# NUC122_v1 register map
File version: 1.0
NUC122_v1 SVD file
Registers are 32-bit, read-write, reset 0x0 unless marked. A register's access mark holds for its fields unless they carry their own. Offsets are from the block's base; lines under a group give offsets from that group; [hi:lo] are bit positions; {n}, {i} and the like mark numbered series; 'fields as' and 'values as' point back to an identical list; <NAME> marks a mode.

## Memory map
0x40004000 WDT size 0x4 — WDT Register Map
0x40008000 RTC size 0x34 — RTC Register Map
0x40010000 TMR01 blocks up to offset 0x30 — TMR Register Map
0x40030000 SPI0 blocks up to offset 0x38 — SPI Register Map
0x40034000 SPI1 blocks up to offset 0x38 — SPI Register Map
0x40040000 PWMA blocks up to offset 0x80 — PWM Register Map
0x40050000 UART0 size 0x34 — UART Register Map
0x40060000 USB blocks up to offset 0x94 — USB Register Map
0x40100000 PS2 size 0x20 — PS2 Register Map
0x40110000 TMR23 blocks up to offset 0x30 — TMR Register Map
0x40120000 I2C size 0x34 — I2C Register Map
0x40150000 UART1 size 0x34 — UART Register Map
0x50000000 GCR blocks up to offset 0x104 — GCR Register Map
0x50000200 CLK blocks up to offset 0x24 — CLK Register Map
0x50000300 INT size 0x88 — INT Register Map
0x50004000 GP blocks up to offset 0x300 — GPIO Register Map
0x5000C000 FMC blocks up to offset 0x1C — FMC Register Map
0xE000E000 SCS blocks up to offset 0xD24 — SCS Register Map

## INT — INT Register Map
Base 0x50000300
{0x0+4i} IRQ{i}_SRC ro reset not defined (i=0..3) — IRQ{i} (BOD) Interrupt Source Identity
  [3:0] INT_SRC — Interrupt Source. Define the interrupt sources for interrupt event.
0x10 IRQ4_SRC ro reset not defined — IRQ4(BOD) Interrupt Source Identity
  fields as IRQ0_SRC
{0x0+4i} IRQ{i}_SRC ro reset not defined (i=5..31) — IRQ{i} (BOD) Interrupt Source Identity
  fields as IRQ0_SRC
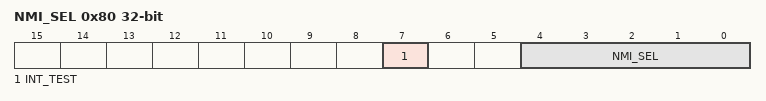
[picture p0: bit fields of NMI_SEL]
0x80 NMI_SEL — NMI Interrupt Source Selection Control Register
  [7] INT_TEST — Interrupt Test Mode (write-protection bit)
  [4:0] NMI_SEL — NMI Interrupt Source Selection. The NMI interrupt to Cortex-M0 can be selected from one of the peripheral interrupts by setting NMI_SEL.
0x84 MCU_IRQ — MCU IRQ Number Identity Register
  [31:0] MCU_IRQ — MCU IRQ Source Register. The MCU_IRQ collects all the interrupts from the peripherals and generates the synchronous interrupt to Cortex-M0. There are two modes to generate interrupt to Cortex-M0, the normal mode and test mode. The MCU_IRQ collects all interrupts from each peripheral and synchronizes them then interrupts the Cortex-M0. When the MCU_IRQ[n] is 0: Set MCU_IRQ[n] 1 will generate an interrupt to Cortex_M0 NVIC[n]. When the MCU_IRQ[n] is 1 (mean an interrupt is assert), set 1 to the MCU_IRQ[n] will clear the interrupt and set MCU_IRQ[n] 0 : no any effect.

## I2C — I2C Register Map
Base 0x40120000
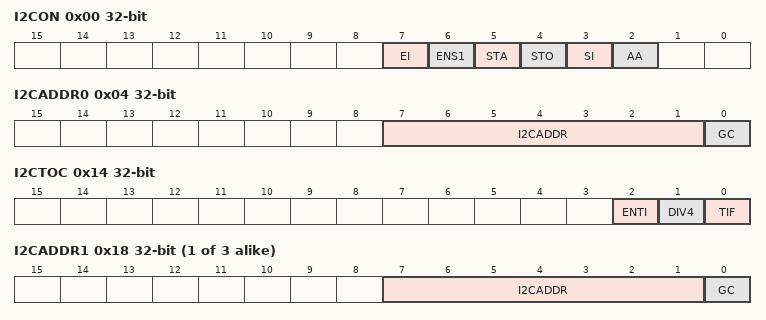
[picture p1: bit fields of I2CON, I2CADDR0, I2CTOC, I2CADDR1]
0x00 I2CON — I2C Control Register
  [7] EI — Enable Interrupt
    0=Disable I2C interrupt; 1=Enable I2C interrupt
  [6] ENS1 — I2C Controller Enable Bit
    0=Disable; 1=Enable
  [5] STA — I2C START Control Bit. Set STA to logic 1 to enter master mode, the I2C hardware sends a START or repeat START condition to bus when the bus is free.
  [4] STO — I2C STOP Control Bit. In master mode, set STO to transmit a STOP condition to bus then I2C hardware will check the bus condition if a STOP condition is detected this bit will be cleared by hardware automatically. In a slave mode, set STO resets I2C hardware to the defined "not addressed" slave mode. This means it is NO LONGER in the slave receiver mode to receive data from the master transmit device.
  [3] SI — I2C Interrupt Flag. When a new I2C state is present in the I2CSTATUS register, the SI flag is set by hardware, and if bit EI (I2CON [7]) is set, the I2C interrupt is requested. SI must be cleared by software. Clear SI is by writing 1 to this bit.
  [2] AA — Assert Acknowledge Control Bit
0x04 I2CADDR0 — I2C Slave Address Register 0
  [7:1] I2CADDR — I2C Address Register. The content of this register is irrelevant when I2C is in master mode. In the slave mode, the seven most significant bits must be loaded with the chip's own address. The I2C hardware will react if one of the addresses is matched.
  [0] GC — General Call Function
    0=Disable General Call Function; 1=Enable General Call Function
0x08 I2CDAT — I2C Data Register
  [7:0] I2CDAT — I2C Data Register. Bit [7:0] is located with the 8-bit transferred data of I2C serial port.
0x0C I2CSTATUS ro reset 0xF8
  [7:0] I2CSTATUS — I2C Status Register. The status register of I2C:
0x10 I2CLK — I2C Clock Divider Register
  [7:0] I2CLK
0x14 I2CTOC — I2C Time-Out Counter Register
  [2] ENTI — Time-out Counter Enable. When Enable, the 14 bit time-out counter will start counting when SI is clear. Writing 1 to the SI flag will reset counter and re-start up counting after SI is cleared.
    0=Time-out counter Disable; 1=Time-out counter Enable
  [1] DIV4 — Time-Out Counter Input Clock is Divided by 4. When Enable, The time-Out period is extended 4 times.
    0=The Time-out counter input clock divided by 4 Disable; 1=The Time-out counter input clock divided by 4 Enable
  [0] TIF — Time-Out Flag. This bit is set by H/W when I2C time-out happened and it can interrupt CPU if I2C interrupt enable bit (EI) is set to 1. S/W can write 1 to clear this bit.
{0x14+4i} I2CADDR{i} (i=1..3) — I2C Slave Address Register {i}
  fields as I2CADDR0
{0x24+4i} I2CADM{i} (i=0..3) — I2C Slave Address Mask Register {i}
  [7:1] I2CADMx — I2C Address Mask Register. I2C bus controllers support multiple address recognition with four address mask register. When the bit in the address mask register is set to one, it means the received corresponding address bit is don't-care. If the bit is set to zero, that means the received corresponding register bit should be exactly the same as address register.
    0=Mask disable (the received corresponding register bit should be exactly the same as address register.); 1=Mask enable (the received corresponding address bit is don't care.)
